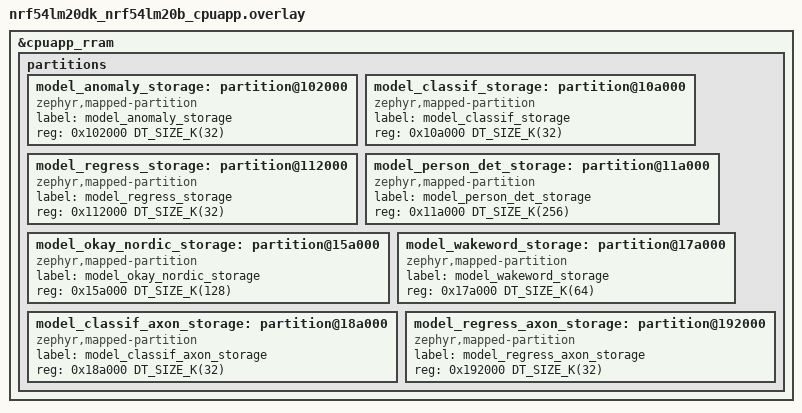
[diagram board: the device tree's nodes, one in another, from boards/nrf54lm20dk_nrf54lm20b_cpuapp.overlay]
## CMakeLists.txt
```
#
# Copyright (c) 2026 Nordic Semiconductor ASA
#
# SPDX-License-Identifier: LicenseRef-Nordic-5-Clause
#

cmake_minimum_required(VERSION 3.20.0)

find_package(Zephyr REQUIRED HINTS $ENV{ZEPHYR_BASE})
project(nrf_edgeai_multi_model_sample)

include(${ZEPHYR_SDK_EDGE_AI_MODULE_DIR}/lib/model_ota/cmake/model_ota.cmake)

set(ANOMALY_MODEL_DIR ${ZEPHYR_SDK_EDGE_AI_MODULE_DIR}/samples/nrf_edgeai/anomaly/src/nrf_edgeai_generated)
set(CLASSIF_MODEL_DIR ${ZEPHYR_SDK_EDGE_AI_MODULE_DIR}/samples/nrf_edgeai/classification/src/nrf_edgeai_generated/Neuton)
set(CLASSIF_AXON_MODEL_DIR ${ZEPHYR_SDK_EDGE_AI_MODULE_DIR}/samples/nrf_edgeai/classification/src/nrf_edgeai_generated/Axon)
set(REGRESS_MODEL_DIR ${ZEPHYR_SDK_EDGE_AI_MODULE_DIR}/samples/nrf_edgeai/regression/src/nrf_edgeai_generated/Neuton)
set(REGRESS_AXON_MODEL_DIR ${ZEPHYR_SDK_EDGE_AI_MODULE_DIR}/samples/nrf_edgeai/regression/src/nrf_edgeai_generated/Axon)
set(CLASSIF_AXON_MODEL_SRC ${CLASSIF_AXON_MODEL_DIR}/nrf_edgeai_user_model.c)
set(CLASSIF_AXON_MODEL_HEADER ${CLASSIF_AXON_MODEL_DIR}/nrf_edgeai_user_model_axon.h)
set(REGRESS_AXON_MODEL_SRC ${REGRESS_AXON_MODEL_DIR}/nrf_edgeai_user_model.c)
set(REGRESS_AXON_MODEL_HEADER ${REGRESS_AXON_MODEL_DIR}/nrf_edgeai_user_model_axon.h)
set(WW_MODEL_DIR ${ZEPHYR_SDK_EDGE_AI_MODULE_DIR}/applications/ww_kws/src/ww/nrf_edgeai_generated)
set(WW_MODEL_SRC ${WW_MODEL_DIR}/nrf_edgeai_user_model.c)
set(WW_MODEL_HEADER ${WW_MODEL_DIR}/nrf_edgeai_user_model_axon.h)
set(PERSON_DET_DIR ${ZEPHYR_SDK_EDGE_AI_MODULE_DIR}/applications/person_detection/src)
set(OKAY_NORDIC_DIR ${ZEPHYR_SDK_EDGE_AI_MODULE_DIR}/samples/axon/axon_low_power/src)

set(NEUTON_MODEL_SOURCES
  ${ANOMALY_MODEL_DIR}/nrf_edgeai_user_model.c
  ${CLASSIF_MODEL_DIR}/nrf_edgeai_user_model.c
  ${REGRESS_MODEL_DIR}/nrf_edgeai_user_model.c
)

set(PERSON_DET_HEADER ${PERSON_DET_DIR}/generated/nrf_axon_model_person_det_.h)
set(OKAY_NORDIC_HEADER ${OKAY_NORDIC_DIR}/generated/nrf_axon_model_okay_nordic.h)

target_include_directories(app PRIVATE include)

target_sources(app PRIVATE
  src/main.c
  src/test_anomaly.c
  src/test_classification.c
  src/test_regression.c
)

if(CONFIG_MULTI_MODEL_AXON)
  target_sources(app PRIVATE
    src/test_classification_axon.c
    src/test_regression_axon.c
    src/test_wakeword.c
    src/test_person_det.c
    src/test_okay_nordic.c
    ${PERSON_DET_DIR}/postprocessing.c
  )
endif()

# Neuton models are partition-loaded when CONFIG_MODEL_OTA_NEUTON is enabled; compiled directly
# into the app otherwise.
if(NOT CONFIG_MODEL_OTA_NEUTON)
  target_sources(app PRIVATE ${NEUTON_MODEL_SOURCES})
endif()

# Edge AI Lab solutions with an Axon backend are partition-loaded when Axon OTA is enabled.
if(CONFIG_MULTI_MODEL_AXON AND NOT CONFIG_MODEL_OTA_AXON)
  target_sources(app PRIVATE
    ${WW_MODEL_SRC}
    ${CLASSIF_AXON_MODEL_SRC}
    ${REGRESS_AXON_MODEL_SRC}
  )
endif()

target_include_directories(app PRIVATE
  ${ANOMALY_MODEL_DIR}
  ${CLASSIF_MODEL_DIR}
  ${REGRESS_MODEL_DIR}
  ${WW_MODEL_DIR}
  ${PERSON_DET_DIR}
  ${PERSON_DET_DIR}/generated
  ${OKAY_NORDIC_DIR}
  ${OKAY_NORDIC_DIR}/generated
)

if(CONFIG_MODEL_OTA_NEUTON)
  model_ota_edgeai_neuton_model(TARGET gear_anomaly SOLUTION_ID 90360 VERSION 1.0.0
                                PARTITION_NODELABEL model_anomaly_storage NEURONS_CAP 20
                                MODEL_SRC ${ANOMALY_MODEL_DIR}/nrf_edgeai_user_model.c)
  model_ota_edgeai_neuton_model(TARGET gesture_class SOLUTION_ID 90449 VERSION 1.0.0
                                PARTITION_NODELABEL model_classif_storage NEURONS_CAP 80
                                MODEL_SRC ${CLASSIF_MODEL_DIR}/nrf_edgeai_user_model.c)
  model_ota_edgeai_neuton_model(TARGET temp_regress SOLUTION_ID 90508 VERSION 1.0.0
                                PARTITION_NODELABEL model_regress_storage NEURONS_CAP 2
                                MODEL_SRC ${REGRESS_MODEL_DIR}/nrf_edgeai_user_model.c)
endif()

if(CONFIG_MULTI_MODEL_AXON AND CONFIG_MODEL_OTA_AXON)
  model_ota_edgeai_axon_model(TARGET wakeword SOLUTION_ID 36711 VERSION 1.0.0
                              PARTITION_NODELABEL model_wakeword_storage
                              MODEL_SRC ${WW_MODEL_SRC} HEADER ${WW_MODEL_HEADER}
                              PERSISTENT_VARS_CAP 1160)
  model_ota_edgeai_axon_model(TARGET classif_axon SOLUTION_ID 36237 VERSION 1.0.0
                              PARTITION_NODELABEL model_classif_axon_storage
                              MODEL_SRC ${CLASSIF_AXON_MODEL_SRC}
                              HEADER ${CLASSIF_AXON_MODEL_HEADER})
  model_ota_edgeai_axon_model(TARGET regress_axon SOLUTION_ID 36025 VERSION 1.0.0
                              PARTITION_NODELABEL model_regress_axon_storage
                              MODEL_SRC ${REGRESS_AXON_MODEL_SRC}
                              HEADER ${REGRESS_AXON_MODEL_HEADER})

  # ALLOCATE_PACKED_OUTPUT: keeps this build path (app-owned storage wired into the
  # linked image's packed_output_buf) covered by every OTA build/flash of this sample.
  model_ota_axon_model(TARGET person_det VERSION 1.0.0
                       PARTITION_NODELABEL model_person_det_storage
                       HEADER ${PERSON_DET_HEADER}
                       ALLOCATE_PACKED_OUTPUT)
  model_ota_axon_model(TARGET okay_nordic VERSION 1.0.0
                       PARTITION_NODELABEL model_okay_nordic_storage
                       HEADER ${OKAY_NORDIC_HEADER}
                       PERSISTENT_VARS_CAP 1160)
endif()

if(CONFIG_MODEL_OTA)
  model_ota_finalize()
endif()
```

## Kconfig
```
#
# Copyright (c) 2026 Nordic Semiconductor ASA
#
# SPDX-License-Identifier: LicenseRef-Nordic-5-Clause
#

menu "Multi-model sample"

config MULTI_MODEL_AXON
	bool "Include the Axon-backed models"
	default y
	help
	  Build and run the models with an Axon backend: the pure Axon ones (person
	  detection, okay_nordic) and the Edge AI Lab solutions whose backend is Axon
	  (wakeword, classification, regression). The Neuton models always build.

config SCORE_THRESHOLD
	int "Person detection score threshold, in per mille"
	default 250
	range 0 1000
	help
	  Confidence score threshold for person detection postprocessing.

config IOU_THRESHOLD
	int "Person detection IoU threshold, in per mille"
	default 450
	range 0 1000
	help
	  Intersection-over-Union threshold for non-maximum suppression.

endmenu

source "Kconfig.zephyr"
```

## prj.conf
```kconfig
#
# Copyright (c) 2026 Nordic Semiconductor ASA
#
# SPDX-License-Identifier: LicenseRef-Nordic-5-Clause
#

CONFIG_NRF_EDGEAI=y
CONFIG_NRF_AXON=y
CONFIG_NRF_AXON_INTERLAYER_BUFFER_SIZE=229376
CONFIG_NRF_AXON_PSUM_BUFFER_SIZE=0
CONFIG_FPU=y
CONFIG_NCS_SAMPLES_DEFAULTS=y
CONFIG_CBPRINTF_FP_SUPPORT=y
CONFIG_SCORE_THRESHOLD=250
CONFIG_IOU_THRESHOLD=450

CONFIG_LOG_MODE_IMMEDIATE=y
CONFIG_ASSERT_NO_MSG_INFO=n
CONFIG_RESET_ON_FATAL_ERROR=n
```

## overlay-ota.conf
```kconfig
#
# Copyright (c) 2026 Nordic Semiconductor ASA
#
# SPDX-License-Identifier: LicenseRef-Nordic-5-Clause
#
# Model-only OTA overlay for the multi_model sample (nRF54LM20 DK boards only): the Neuton
# models, the person-detection/okay_nordic Axon models, and the wakeword/classification/
# regression Edge AI Lab solutions' compiled Axon models are all built as linked partition
# images. Build with:
#   west build -b nrf54lm20dk/nrf54lm20b/cpuapp -- -DEXTRA_CONF_FILE=overlay-ota.conf

CONFIG_MODEL_OTA_TESTING=y
CONFIG_MODEL_OTA=y
CONFIG_MODEL_OTA_NEUTON=y
CONFIG_MODEL_OTA_AXON=y

# model_image_load_*() dependencies.
CONFIG_FLASH=y
CONFIG_CRC=y
```

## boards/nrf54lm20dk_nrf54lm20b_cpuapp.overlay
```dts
/*
 * Copyright (c) 2026 Nordic Semiconductor ASA
 *
 * SPDX-License-Identifier: LicenseRef-Nordic-5-Clause
 */

/*
 * Model-only OTA: repurpose the unused (no-MCUboot) slot1_partition region as dedicated
 * model_storage partitions (three Neuton models + five Axon models, including the Edge AI Lab
 * wakeword/classification/regression solutions' Axon backends).
 * -DEXTRA_CONF_FILE=overlay-ota.conf; harmless (just reserved, unused flash) otherwise.
 *
 * The OTA build emits a standalone <name>_model_partition.hex per model (linked at the matching
 * partition base). Flash one into its partition without disturbing the app or the other models:
 *   nrfutil device program --firmware gear_anomaly_model_partition.hex \
 *       --options chip_erase_mode=ERASE_RANGES_TOUCHED_BY_FIRMWARE,reset=RESET_SYSTEM
 */
/delete-node/ &slot1_partition;

&cpuapp_rram {
	partitions {
		model_anomaly_storage: partition@102000 {
			compatible = "zephyr,mapped-partition";
			label = "model_anomaly_storage";
			reg = <0x102000 DT_SIZE_K(32)>;
		};

		model_classif_storage: partition@10a000 {
			compatible = "zephyr,mapped-partition";
			label = "model_classif_storage";
			reg = <0x10a000 DT_SIZE_K(32)>;
		};

		model_regress_storage: partition@112000 {
			compatible = "zephyr,mapped-partition";
			label = "model_regress_storage";
			reg = <0x112000 DT_SIZE_K(32)>;
		};

		model_person_det_storage: partition@11a000 {
			compatible = "zephyr,mapped-partition";
			label = "model_person_det_storage";
			reg = <0x11a000 DT_SIZE_K(256)>;
		};

		model_okay_nordic_storage: partition@15a000 {
			compatible = "zephyr,mapped-partition";
			label = "model_okay_nordic_storage";
			reg = <0x15a000 DT_SIZE_K(128)>;
		};

		model_wakeword_storage: partition@17a000 {
			compatible = "zephyr,mapped-partition";
			label = "model_wakeword_storage";
			reg = <0x17a000 DT_SIZE_K(64)>;
		};

		model_classif_axon_storage: partition@18a000 {
			compatible = "zephyr,mapped-partition";
			label = "model_classif_axon_storage";
			reg = <0x18a000 DT_SIZE_K(32)>;
		};

		model_regress_axon_storage: partition@192000 {
			compatible = "zephyr,mapped-partition";
			label = "model_regress_axon_storage";
			reg = <0x192000 DT_SIZE_K(32)>;
		};
	};
};
```

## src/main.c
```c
/*
 * Copyright (c) 2026 Nordic Semiconductor ASA
 *
 * SPDX-License-Identifier: LicenseRef-Nordic-5-Clause
 */

#include "test_models.h"

#include <zephyr/kernel.h>
#include <zephyr/logging/log.h>

LOG_MODULE_REGISTER(multi_model, LOG_LEVEL_INF);

int main(void)
{
	LOG_INF("Running local multi-model test (Neuton + Edge AI + Axon models)");

	run_anomaly_tests();
	LOG_INF("Anomaly tests passed");

	run_classification_tests();
	LOG_INF("Classification tests passed");

	run_regression_tests();
	LOG_INF("Regression tests passed");

#ifdef CONFIG_MULTI_MODEL_AXON
	run_classification_axon_tests();
	LOG_INF("Axon classification tests passed");

	run_regression_axon_tests();
	LOG_INF("Axon regression tests passed");

	run_wakeword_tests();
	LOG_INF("Wakeword tests passed");

	run_person_det_tests();
	LOG_INF("Person detection tests passed");

	run_okay_nordic_tests();
	LOG_INF("okay_nordic tests passed");
#endif

	while (1) {
		LOG_INF("All multi-model tests completed");
		k_sleep(K_MSEC(5000));
	}

	return 0;
}
```

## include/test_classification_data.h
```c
/*
 * Copyright (c) 2026 Nordic Semiconductor ASA
 *
 * SPDX-License-Identifier: LicenseRef-Nordic-5-Clause
 */

#ifndef TEST_CLASSIFICATION_DATA_H_
#define TEST_CLASSIFICATION_DATA_H_

#include <nrf_edgeai/nrf_edgeai.h>

static const size_t USER_WINDOW_SIZE = 50;     /* Samples per inference window */
static const size_t USER_UNIQ_INPUTS_NUM = 1;  /* Single input: acceleration magnitude */
static const size_t USER_MODELS_CLASS_NUM = 7; /* 7 parcel state classes */

/**
 *  Class 0: IDLE STATE - Parcel at Rest
 *
 * Characteristics of the idle state:
 *   - Acceleration values cluster tightly around 1000 mG (gravitational acceleration baseline)
 *   - Minimal variation between consecutive samples (stable, static state)
 *   - No significant spikes or sudden changes in acceleration
 *   - Represents a parcel at rest on a surface (shelf, table, ground, stationary truck)
 *
 * Use cases:
 *   - Parcel stored at warehouse awaiting shipment
 *   - Parcel on delivery truck stationary between stops
 *   - Parcel at customer delivery location
 *   - Parcel placed on shelf or table
 *
 * Data characteristics: Consistent baseline with minimal noise, typical for gravitational field
 */
static const flt32_t CLASS_0_PARCEL_IDLE_ACCEL_DATA[] = {
	1019.234877, 1018.652192, 1016.69811,  1019.901583, 1017.029378, 1014.381015, 1016.604559,
	1016.201444, 1016.23062,  1018.555051, 1016.319548, 1017.072842, 1018.494815, 1013.635677,
	1017.41575,  1021.132362, 1018.691935, 1019.848198, 1016.620341, 1011.873442, 1020.299764,
	1018.478126, 1015.541777, 1014.450299, 1013.253033, 1015.282387, 1016.849032, 1021.09152,
	1017.657982, 1013.24848,  1018.48856,  1013.41613,  1018.465645, 1017.460544, 1014.099637,
	1016.850408, 1016.396988, 1016.185508, 1014.927525, 1019.275502, 1017.403871, 1016.319314,
	1018.377489, 1019.466485, 1019.221851, 1013.788435, 1015.948113, 1014.715299, 1018.539064,
	1014.715299,
};

/**
 *  Class 1: SHAKING STATE - Parcel Vibrating or Experiencing Continuous Motion
 *
 * Characteristics of the shaking state:
 *   - Wide variation in acceleration values (ranging 629–3505 mG across the window)
 *   - High-frequency oscillations with rapid changes between consecutive samples
 *   - Peaks and valleys in the signal indicate repetitive shaking or vibration pattern
 *   - Elevated baseline compared to idle state, indicating active motion
 *
 * Use cases:
 *   - Parcel in vehicle traveling on rough or unpaved road
 *   - Parcel being shaken by delivery handler during transport
 *   - Parcel near vibrating machinery or equipment
 *   - Parcel experiencing turbulence during air transport
 *
 * Data characteristics: Oscillatory pattern with significant amplitude variation
 */
static const flt32_t CLASS_1_PARCEL_SHAKING_ACCEL_DATA[] = {
	832.512589,  1272.162323, 1263.232939, 1489.776683, 1859.176281, 1772.024529, 1622.484949,
	1421.231322, 988.9233308, 2904.564726, 1004.390724, 961.4903516, 1569.262094, 1926.891127,
	2159.370306, 1897.586384, 1533.182266, 2626.996728, 1044.248622, 866.9409276, 953.1315255,
	970.2099379, 1587.471444, 1810.551686, 1633.204426, 1730.792617, 2137.291854, 629.6878458,
	1069.066947, 1052.676461, 1091.051232, 1590.295378, 1840.453506, 1829.107198, 1790.32045,
	3505.788281, 1398.574137, 1089.641059, 625.6990249, 854.0307434, 1191.972966, 1523.862829,
	1490.407087, 1600.889671, 1487.519159, 1112.465548, 1909.979213, 1078.403761, 971.6052426,
	872.8287226,
};

/**
 *  Class 2: IMPACT EVENT - Sudden Collision or Drop
 *
 * Characteristics of the impact state:
 *   - Baseline values ~1000–1400 mG (idle/stable state before and after impact)
 *   - Extreme acceleration spike in middle of window (5943–6924 mG, approximately 7x gravity)
 *   - Sharp, isolated peak indicating instantaneous collision or drop event
 *   - Recovery to normal levels immediately after impact spike
 *   - Asymmetric acceleration profile with clear before/after pattern
 *
 * Use cases:
 *   - Parcel dropped from height or accidentally thrown
 *   - Parcel collides with wall, table, or other object during handling
 *   - Parcel experiences sharp impact during loading/unloading operations
 *   - Parcel falls from moving vehicle or conveyor belt
 *
 * Risk Assessment: High risk for potential damage to contents
 * Data characteristics: Baseline + single large impulse, distinctive pattern for detection
 */
static const flt32_t CLASS_2_PARCEL_IMPACT_ACCEL_DATA[] = {
	1015.482154, 1014.753436, 1014.523099, 1012.472024, 1009.822764, 1013.528832, 1010.94256,
	1014.375469, 1010.949774, 1013.925464, 1015.508712, 1012.451178, 968.8407378, 1393.710166,
	5943.221118, 6924.142149, 4296.249304, 3458.151271, 2119.268542, 3263.52814,  1881.500201,
	1479.332158, 1364.573158, 2317.111272, 3159.792859, 2391.741083, 1305.986745, 1169.182085,
	1079.52232,  1048.65378,  1196.683715, 1054.96444,  1147.454278, 971.4221942, 1054.533138,
	1005.604551, 998.3117395, 1026.769424, 991.8001837, 1026.298981, 1007.115343, 1014.293972,
	1007.958389, 1009.272635, 1015.343811, 1013.057529, 1013.781359, 1012.335122, 1011.281924,
	1014.560157,

};

/**
 *  Class 3: FREE FALL STATE - Parcel Unsupported in Air
 *
 * Characteristics of the free fall state:
 *   - Very low acceleration values (15–82 mG, approximately 0.1–0.8x gravity)
 *   - Consistent low baseline throughout the window
 *   - Absence of gravitational acceleration component (sensor in inertial frame)
 *   - Minimal variation, indicating uniform free-fall motion
 *   - Dramatic difference from idle state (which is ~1000 mG)
 *
 * Use cases:
 *   - Parcel dropped and falling under gravity alone
 *   - Parcel suspended or lifted without support (losing contact with surface)
 *   - Parcel in flight during drone or aerial delivery
 *   - Parcel ejected from moving vehicle
 *
 * Risk Assessment: Critical - indicates loss of support or drop in progress
 * Data characteristics: Low constant acceleration, inverse of idle state pattern
 */
static const flt32_t CLASS_3_PARCEL_FREE_FALL_ACCEL_DATA[] = {
	36.87388192, 32.60300207, 29.4674831,  32.69417905, 34.11116509, 33.15887284, 33.85626394,
	32.15342346, 52.59657571, 36.6853006,  38.54968347, 35.5160419,	 48.3840372,  47.2611057,
	39.59571977, 39.79519569, 47.38188498, 50.11275303, 55.69724245, 64.75752645, 70.27411802,
	68.7569314,  68.42144611, 66.124,      75.38968258, 58.17801248, 81.70503133, 81.17282629,
	74.35437106, 62.17788379, 63.89306679, 46.27838078, 43.04231927, 39.9609133,  39.70982871,
	34.28699252, 43.81753603, 27.73132727, 27.37479921, 46.95272669, 24.82332774, 30.18310574,
	37.00201876, 44.0080229,  39.55886449, 162.4691915, 50.70270683, 15.83370127, 75.95418619,
	82.38026851,

};

/**
 *  Class 4: CARRYING STATE - Being Transported by Handler
 *
 * Characteristics of the carrying state:
 *   - Moderate acceleration variation (793–1350 mG range)
 *   - Gradual, smooth transitions between acceleration values
 *   - No sharp spikes or sudden changes characteristic of impacts
 *   - Pattern reflects natural human motion (walking, arm swinging, body sway)
 *   - Organized rhythmic fluctuation corresponding to periodic step patterns
 *   - Distinctly different from mechanical vibration (more organic signal)
 *
 * Use cases:
 *   - Delivery courier walking with parcel in hand or in arms
 *   - Handler carrying parcel to customer door
 *   - Parcel held during package transfer operations
 *   - Manual transport up stairs or through buildings
 *
 * Quality Assessment: Normal, gentle handling with no impact events
 * Data characteristics: Smooth oscillatory pattern reflecting human locomotion
 */
static const flt32_t CLASS_4_PARCEL_CARRYING_ACCEL_DATA[] = {
	1076.406463, 1109.062753, 1161.315764, 1237.303839, 1304.16174,	 1350.922984, 1241.533046,
	1058.547397, 936.9035098, 903.8836329, 909.9999218, 969.2561481, 1018.445741, 978.245237,
	898.4931508, 820.9886822, 793.33496,   823.5297855, 861.7252695, 896.6489743, 934.029546,
	949.6519496, 934.6501455, 959.1392024, 1009.025175, 1096.235981, 1187.678992, 1166.728833,
	1151.409319, 1130.995037, 1206.818376, 1211.209389, 1234.399883, 1316.256909, 1192.097129,
	935.7616639, 849.2381705, 855.3595664, 875.9844676, 940.2683021, 979.1213199, 974.3049546,
	894.6000374, 830.5673266, 806.1867451, 848.9594567, 879.9365677, 904.6198895, 916.9955333,
	963.7698856,

};

/**
 *  Class 5: IN CAR STATE - Parcel Inside Vehicle During Transport
 *
 * Characteristics of the in-car state:
 *   - Moderate, steady acceleration (920–1200 mG throughout the window)
 *   - Smoother variation compared to hand-carried courier handling
 *   - Vehicle suspension system and road vibration create gentle oscillations
 *   - Less organic (human-like) motion pattern; more mechanical (vehicle-like) signature
 *   - Baseline elevated from idle (~1000 mG) due to vehicle motion
 *
 * Use cases:
 *   - Parcel on shelf or floor of moving delivery van
 *   - Parcel in cargo area of delivery truck during road transport
 *   - Parcel on seat or seat belt secured in personal vehicle
 *   - Parcel in container being transported between warehouses
 *
 * Quality Assessment: Protected transport with minimal manual handling and impacts
 * Data characteristics: Smooth mechanical oscillation from vehicle suspension
 */
static const flt32_t CLASS_5_PARCEL_IN_CAR_ACCEL_DATA[] = {
	1020.14299,  1172.412078, 974.2434799, 1081.052374, 936.2345817, 1076.324048, 952.8650187,
	958.4387398, 919.7921364, 945.1008577, 1010.444803, 1048.425866, 954.5281871, 934.6416098,
	1039.243636, 983.2000815, 1106.467282, 1022.459808, 905.5254547, 1021.745856, 1036.285954,
	1061.250757, 1039.194138, 940.8242922, 1076.395069, 1059.220609, 1131.268418, 973.8779736,
	1029.466912, 1062.131636, 1077.031533, 1055.016753, 972.2285251, 1046.442069, 993.0253833,
	1035.990238, 1008.750742, 1035.737579, 1041.367931, 1042.022619, 960.7748412, 1037.639083,
	977.0186869, 990.7190264, 1054.852976, 979.9177917, 997.7978969, 1034.345125, 959.2851854,
	1041.668807,
};

/**
 *  Class 6: PLACED STATE - Active Placement or Lowering Motion
 *
 * Characteristics of the placed state:
 *   - Starts with variable mid-range acceleration (1000–1400 mG)
 *   - Sharp drop to very low value (~76 mG) in middle of window (near free-fall)
 *   - Recovery back to stable ~1000 mG (landed and resting on surface)
 *   - Signature pattern: acceleration during descent followed by impact landing
 *   - Asymmetric temporal profile: active descent phase then static rest phase
 *   - Distinctive from pure free fall (has initial and final support)
 *
 * Use cases:
 *   - Parcel being gently placed down on shelf or table
 *   - Parcel being lowered to ground by handler or crane
 *   - Parcel being set down in customer delivery location
 *   - Parcel being suspended then released on support surface
 *
 * Quality Assessment: Intentional placement, potentially fragile/careful handling
 * Data characteristics: Descent profile with clear phase transition from motion to rest
 */
static const flt32_t CLASS_6_PARCEL_PLACED_ACCEL_DATA[] = {
	1028.084177, 1009.771942, 1023.977186, 1012.436213, 1020.685482, 1018.459741, 1013.2669,
	1402.760074, 1072.973569, 1044.170967, 996.3176143, 1090.362426, 1024.921702, 1037.91844,
	1052.900034, 1062.920713, 1020.651183, 966.0045051, 906.5110973, 871.8735271, 824.1462199,
	799.1876862, 776.2963823, 765.3527818, 802.7631891, 1163.179632, 1016.619697, 76.78637744,
	1418.807213, 1005.875935, 1033.329744, 1119.948199, 946.126825,	 1083.038163, 949.8881454,
	1064.367743, 978.8891064, 1023.622866, 1026.007989, 1002.963002, 1026.46044,  1008.698302,
	1032.013223, 1016.890865, 1016.071373, 1022.803209, 1009.949278, 1007.64987,  997.3304425,
	1062.455154,
};

/* Enumeration of parcel state classes */
typedef enum {
	MODEL_CLASS_IDLE = 0,
	MODEL_CLASS_SHAKING,
	MODEL_CLASS_IMPACT,
	MODEL_CLASS_FREE_FALL,
	MODEL_CLASS_CARRYING,
	MODEL_CLASS_IN_CAR,
	MODEL_CLASS_PLACED,
} user_model_class_t;

/* Human-readable labels for each parcel state class */
static const char *const USER_MODEL_LABELS_STR[] = {
	[MODEL_CLASS_IDLE] = "Idle",	     [MODEL_CLASS_SHAKING] = "Shaking",
	[MODEL_CLASS_IMPACT] = "Impact",     [MODEL_CLASS_FREE_FALL] = "Free Fall",
	[MODEL_CLASS_CARRYING] = "Carrying", [MODEL_CLASS_IN_CAR] = "in Car",
	[MODEL_CLASS_PLACED] = "Placed",
};


#endif /* TEST_CLASSIFICATION_DATA_H_ */
```

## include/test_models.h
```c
/*
 * Copyright (c) 2026 Nordic Semiconductor ASA
 *
 * SPDX-License-Identifier: LicenseRef-Nordic-5-Clause
 */

#ifndef TEST_MODELS_H_
#define TEST_MODELS_H_

void run_anomaly_tests(void);
void run_classification_tests(void);
void run_regression_tests(void);

#ifdef CONFIG_MULTI_MODEL_AXON
void run_classification_axon_tests(void);
void run_regression_axon_tests(void);
void run_wakeword_tests(void);
void run_person_det_tests(void);
void run_okay_nordic_tests(void);
#endif

#endif /* TEST_MODELS_H_ */
```

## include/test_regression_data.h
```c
/*
 * Copyright (c) 2026 Nordic Semiconductor ASA
 *
 * SPDX-License-Identifier: LicenseRef-Nordic-5-Clause
 */

#ifndef TEST_REGRESSION_DATA_H_
#define TEST_REGRESSION_DATA_H_

#include <nrf_edgeai/nrf_edgeai.h>

static const size_t USER_WINDOW_SIZE = 1;	 /* Samples per inference window */
static const size_t USER_UNIQ_INPUTS_NUM = 9;	 /* Gas sensor and environmental input features */
static const size_t USER_MODELS_OUTPUTS_NUM = 1; /* Single air quality prediction output */
static const flt32_t INVALID_PREDICTION_VALUE = -9999.0f; /* Invalid prediction indicator */
static const flt32_t EXPECTED_MODEL_MAE = 2.0f; /* Expected Mean Absolute Error for validation */

/**
 * @brief Test Dataset Structure and Values
 *
 * This structure defines the schema for test samples:
 * - COGT: CO sensor (main carbon monoxide detector)
 * - PT08S1-5: Five metal oxide semiconductor (MOS) sensors:
 *   * PT08S1: CO sensor output
 *   * PT08S2: NMHC (non-methane hydrocarbons) sensor
 *   * PT08S3: NOx (nitrogen oxides) sensor
 *   * PT08S4: NO2 (nitrogen dioxide) sensor
 *   * PT08S5: O3 (ozone) sensor
 * - T: Temperature in Celsius (affects pollutant concentration and sensor response)
 * - RH: Relative Humidity in percentage (influences sensor readings and pollutant behavior)
 * - AH: Absolute Humidity in kg/m³ (moisture content in air)
 * - target: Ground truth air quality value (used for validation)
 *
 * @note All sensor values are normalized or raw readings from the measurement device.
 * The 29 test samples cover various environmental conditions to validate model performance
 * across different temperature, humidity, and pollution levels.
 */
struct {
	flt32_t COGT;	/**< CO sensor reading */
	flt32_t PT08S1; /**< PT08 MOS sensor 1 (CO) */
	flt32_t PT08S2; /**< PT08 MOS sensor 2 (NMHC) */
	flt32_t PT08S3; /**< PT08 MOS sensor 3 (NOx) */
	flt32_t PT08S4; /**< PT08 MOS sensor 4 (NO2) */
	flt32_t PT08S5; /**< PT08 MOS sensor 5 (O3) */
	flt32_t T;	/**< Temperature in Celsius */
	flt32_t RH;	/**< Relative Humidity in percentage */
	flt32_t AH;	/**< Absolute Humidity in kg/m³ */
	flt32_t target; /**< Ground truth air quality value */
} static const USER_INPUT_DATA[] = {
	[0] = {2.7, 1146, 1125, 846, 1511, 1016, 33.4, 20.3, 1.027, 14.3},
	[1] = {3.3, 1272, 1328, 567, 2085, 1463, 19.6, 54.3, 1.2278, 21.1},
	[2] = {0.6, 919, 571, 1017, 1082, 521, 13.5, 63.8, 0.9801, 1.8},
	[3] = {1.7, 1162, 1019, 622, 1904, 1178, 27.9, 56.5, 2.0895, 11.1},
	[4] = {2.7, 1381, 1227, 595, 1903, 1845, 29.8, 33.1, 1.3693, 17.6},
	[5] = {1.1, 1010, 679, 854, 1046, 889, 5, 82.9, 0.73, 3.4},
	[6] = {1.9, 1055, 1037, 635, 1632, 1161, 25.3, 41.7, 1.3247, 11.6},
	[7] = {3.4, 1417, 1303, 635, 1964, 1752, 20.7, 40, 0.9639, 20.2},
	[8] = {2, 1273, 988, 563, 1387, 1257, 24.1, 33.3, 0.9881, 10.3},
	[9] = {4.8, 1435, 1429, 499, 2072, 1449, 21.7, 59.1, 1.5115, 25},
	[10] = {1, 1003, 635, 829, 1235, 711, 13.7, 80.6, 1.2528, 2.7},
	[11] = {1.3, 1259, 1152, 610, 1165, 1569, 8.2, 36.8, 0.4016, 15.1},
	[12] = {2.7, 1229, 1114, 598, 1723, 1247, 19.7, 0.73, 0.6708, 13.9},
	[13] = {2.8, 1261, 1258, 629, 1813, 1315, 43.4, 14.8, 1.2882, 18.6},
	[14] = {1.3, 997, 752, 837, 952, 724, 11.8, 34.4, 0.4758, 4.8},
	[15] = {1.3, 942, 846, 980, 1615, 905, 21.7, 50.8, 1.3019, 6.7},
	[16] = {0.6, 883, 518, 1135, 962, 606, 3.3, 84.5, 0.6612, 1.2},
	[17] = {3.2, 1174, 1264, 670, 1598, 1287, 28.9, 21.3, 0.8382, 18.8},
	[18] = {0.5, 748, 595, 1208, 1089, 677, 12.8, 0.598, 0.8801, 2.2},
	[19] = {1.4, 920, 783, 1046, 1550, 588, 24.5, 0.384, 1.1669, 5.4},
	[20] = {1.3, 906, 790, 893, 837, 642, 12.3, 19.3, 0.274, 5.5},
	[21] = {0.6, 882, 563, 978, 936, 660, 8.9, 0.527, 0.6034, 1.7},
	[22] = {3.4, 1403, 1443, 508, 2234, 1811, 25.2, 0.386, 1.2215, 25.6},
	[23] = {3.9, 1297, 1102, 507, 1375, 1583, 18.2, 0.363, 0.7487, 13.6},
	[24] = {1.3, 987, 800, 989, 1462, 658, 15.5, 0.571, 0.996, 5.7},
	[25] = {1.3, 869, 866, 1107, 1212, 596, 0.238, 0.145, 0.4222, 7.2},
	[26] = {3.2, 1336, 1340, 540, 2049, 1400, 21.3, 0.635, 1.5941, 21.6},
	[27] = {1, 955, 723, 1129, 1393, 559, 27.7, 0.258, 0.9467, 4.2},
	[28] = {4.3, 1373, 1364, 597, 2005, 1745, 33.7, 0.226, 1.1658, 22.5}};


#endif /* TEST_REGRESSION_DATA_H_ */
```

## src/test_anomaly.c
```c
/*
 * Copyright (c) 2025 Nordic Semiconductor ASA
 *
 * SPDX-License-Identifier: LicenseRef-Nordic-5-Clause
 */

/**
 * @file test_anomaly.c
 * @brief Mechanical Gear Anomaly Detection Model using Vibration Analysis
 *
 * This file implements an anomaly detection neural network model for monitoring gear health
 * using multi-axis vibration data, enabling predictive maintenance and early fault detection.
 *
 * @details
 * **Model Purpose:** Detect abnormal vibration patterns indicating gear degradation, wear,
 * misalignment, or bearing failure using machine learning on dual-axis accelerometer data.
 *
 * **Input Features (2 total):**
 *   - Sensor 1: X-axis vibration (radial direction) in m/s^2
 *   - Sensor 2: Y-axis vibration (axial/tangential direction) in m/s^2
 *   - Data format: Interleaved pairs [X1, Y1, X2, Y2, ...] for streaming input
 *   - Window size: 128 consecutive samples per inference cycle
 *
 * **Output:**
 *   - Anomaly Score: Single floating-point value (0.0 to 1.0+)
 *     - Score < 0.000025: Normal operation (healthy gear, no maintenance needed)
 *     - Score >= 0.000025: Anomaly detected (schedule maintenance alert)
 *
 * **Vibration Characteristics:**
 *   - Healthy Gear: Regular, predictable signature (2.42-2.52 m/s^2, tight distribution)
 *     * Dominated by mesh frequency and harmonics
 *     * Stable periodic oscillation, minimal variation
 *     * No impulsive events or amplitude modulation
 *   - Faulty Gear: Erratic, irregular signature (2.40-2.56 m/s^2, wider spread)
 *     * Sidebands and modulation indicating tooth wear/crack
 *     * Random impulsive events from surface degradation
 *     * Non-stationary pattern indicating bearing failure or misalignment
 *
 * **Applications:**
 *   - Predictive maintenance for rotating machinery (pumps, motors, compressors)
 *   - Early fault detection before catastrophic failure occurs
 *   - Condition-based maintenance scheduling to reduce downtime and costs
 *   - Asset health monitoring across industrial facilities
 *   - Quality control and validation of newly manufactured gear units
 *
 * **Validation Approach:**
 *   The model is validated on two representative vibration datasets: one from a healthy
 *   gear (normal operation) and one from a faulty gear (degraded condition). The model
 *   must correctly distinguish between states to confirm proper anomaly detection.
 */

#include <nrf_edgeai/nrf_edgeai.h>

#include <zephyr/kernel.h>
#include <zephyr/logging/log.h>
#include <stdio.h>

LOG_MODULE_REGISTER(multi_anomaly, LOG_LEVEL_INF);

nrf_edgeai_t *nrf_edgeai_user_model_90360(void);

#if defined(CONFIG_MODEL_OTA_NEUTON)
#include <model_ota/model_ota_edgeai.h>

MODEL_OTA_EDGEAI_LOAD_DECL(90360);
#endif

/**
 * @brief Model Configuration Constants
 *
 * These constants define the shape and structure of the gear anomaly detector:
 * - USER_WINDOW_SIZE: Number of vibration samples accumulated before running inference.
 *   A window of 128 samples captures sufficient temporal detail in gear vibration patterns.
 * - USER_UNIQ_INPUTS_NUM: Total number of input features to the model.
 *   Set to 2 for the dual-axis accelerometer (X and Y vibration components).
 * - USER_ANOMALY_THRESHOLD: Classification threshold for anomaly detection.
 *   Scores above this threshold indicate abnormal gear operation requiring maintenance.
 */
#define USER_WINDOW_SIZE       128	 /* Samples per inference window */
#define USER_UNIQ_INPUTS_NUM   2	 /* 2 vibration sensors: axis X and Y */
#define USER_ANOMALY_THRESHOLD 0.000025f /* Anomaly score threshold, high sensitivity */
#define INVALID_ANOMALY_SCORE  10000.0f	 /* Invalid score for test validation */

/**
 *  Healthy Gear Vibration Baseline Data
 *
 * This dataset contains vibration measurements from a well-maintained mechanical gear
 * operating under normal conditions. Used to validate that the model correctly identifies
 * healthy gear operation with a low anomaly score.
 *
 * Data characteristics:
 *   - Sensor 1 (X-axis): Tightly clustered values around 2.42-2.52 m/s^2
 *   - Sensor 2 (Y-axis): Tightly clustered values around 2.42-2.52 m/s^2
 *   - Tight, consistent distribution across both axes
 *   - Regular, predictable oscillation pattern
 *   - Signal periodicity dominated by gear mesh frequency and harmonics
 *   - Stable baseline with no sudden spikes or amplitude modulation
 *
 * Data format:
 *   Interleaved pairs: [X1, Y1, X2, Y2, X3, Y3, ...]
 *   Total 256 values: 128 samples × 2 axes
 *
 * Expected model output:
 *   Anomaly score << USER_ANOMALY_THRESHOLD (well below threshold, indicating healthy state)
 *   Model confidence: High certainty of normal operation
 */
static const flt32_t GOOD_GEAR_MECH_VIBRATION_DATA_2AXIS[USER_WINDOW_SIZE *
							 USER_UNIQ_INPUTS_NUM] = {
	2.523464899, 2.43016754,  2.521493825, 2.430003284, 2.522479362, 2.429674773, 2.521329569,
	2.431810097, 2.522479362, 2.43131733,  2.519358495, 2.430496051, 2.521986593, 2.430660307,
	2.521001056, 2.431153074, 2.521001056, 2.431153074, 2.523957667, 2.431974352, 2.522150849,
	2.430003284, 2.521822337, 2.429839029, 2.524943204, 2.428853495, 2.522643618, 2.429839029,
	2.522479362, 2.430660307, 2.521658081, 2.429839029, 2.520015519, 2.430824563, 2.521001056,
	2.432138608, 2.521822337, 2.431810097, 2.520672544, 2.431645841, 2.521493825, 2.430988818,
	2.522315105, 2.43131733,  2.521986593, 2.431645841, 2.522315105, 2.430496051, 2.522643618,
	2.429510518, 2.522315105, 2.43016754,  2.521165312, 2.429674773, 2.522150849, 2.429510518,
	2.521822337, 2.429839029, 2.521329569, 2.43016754,  2.521493825, 2.429839029, 2.522479362,
	2.429346262, 2.521986593, 2.430660307, 2.521493825, 2.430988818, 2.520344032, 2.430331796,
	2.521165312, 2.429182006, 2.5208368,   2.431974352, 2.522479362, 2.431974352, 2.521329569,
	2.432631375, 2.521165312, 2.431153074, 2.522643618, 2.431810097, 2.523629155, 2.431153074,
	2.52297213,  2.430824563, 2.522479362, 2.430331796, 2.521493825, 2.430331796, 2.520344032,
	2.429510518, 2.522807874, 2.43131733,  2.523629155, 2.429839029, 2.521658081, 2.430824563,
	2.521658081, 2.430824563, 2.521001056, 2.429839029, 2.522479362, 2.430003284, 2.524121923,
	2.428360728, 2.523136386, 2.429510518, 2.521329569, 2.430331796, 2.520672544, 2.431974352,
	2.523629155, 2.431153074, 2.521822337, 2.431153074, 2.521165312, 2.431810097, 2.520508288,
	2.432631375, 2.5208368,	  2.432138608, 2.521329569, 2.431153074, 2.523136386, 2.431153074,
	2.523793411, 2.431645841, 2.520179775, 2.431153074, 2.520672544, 2.431810097, 2.524450436,
	2.429346262, 2.522150849, 2.428689239, 2.521493825, 2.429674773, 2.521493825, 2.429674773,
	2.522150849, 2.430660307, 2.522643618, 2.430496051, 2.522479362, 2.431153074, 2.521165312,
	2.431153074, 2.522807874, 2.429839029, 2.523300642, 2.430824563, 2.52297213,  2.429346262,
	2.522150849, 2.429017751, 2.522150849, 2.430988818, 2.523629155, 2.430496051, 2.523136386,
	2.430660307, 2.522150849, 2.430331796, 2.522479362, 2.430988818, 2.522643618, 2.431974352,
	2.522479362, 2.431153074, 2.522807874, 2.431974352, 2.521329569, 2.432631375, 2.520344032,
	2.431481585, 2.521822337, 2.430003284, 2.522643618, 2.43131733,	 2.523793411, 2.430496051,
	2.522315105, 2.430824563, 2.522807874, 2.430824563, 2.523629155, 2.429510518, 2.523464899,
	2.429182006, 2.521822337, 2.430496051, 2.521822337, 2.430824563, 2.521329569, 2.432302864,
	2.522315105, 2.432467119, 2.521822337, 2.432302864, 2.522315105, 2.432138608, 2.522150849,
	2.430824563, 2.524778948, 2.430003284, 2.522643618, 2.430003284, 2.522479362, 2.430988818,
	2.522807874, 2.432795631, 2.522479362, 2.430496051, 2.523300642, 2.430003284, 2.521658081,
	2.430003284, 2.5208368,	  2.43131733,  2.523629155, 2.431481585, 2.523300642, 2.430660307,
	2.522315105, 2.430660307, 2.522807874, 2.430824563, 2.522315105, 2.430660307, 2.521493825,
	2.430003284, 2.523793411, 2.43016754,  2.523300642, 2.430496051, 2.521493825, 2.430331796,
	2.521822337, 2.43016754,  2.521822337, 2.428853495, 2.523300642, 2.430331796, 2.522150849,
	2.43016754,  2.522315105, 2.431153074, 2.521658081, 2.432302864, 2.523136386, 2.430496051,
	2.521165312, 2.431481585, 2.5208368,   2.430988818,
};

/**
 * Anomalous Gear Vibration Data - Faulty Operation
 *
 * This dataset contains vibration measurements from a defective mechanical gear exhibiting
 * abnormal operating conditions. Used to validate that the model correctly identifies gear
 * faults with an anomaly score above the detection threshold.
 *
 * Data characteristics of defective gear:
 *   - Sensor 1 (X-axis): Wider range 2.40-2.56 m/s^2 (vs. healthy 2.42-2.52 m/s^2)
 *   - Sensor 2 (Y-axis): Wider range 2.40-2.56 m/s^2 (greater variation than healthy)
 *   - Erratic, unpredictable fluctuations across both axes
 *   - Irregular variation pattern with sudden amplitude changes
 *   - Modulation sidebands indicating gear tooth damage or misalignment
 *   - Random impulsive events with high-amplitude spikes (reaching 2.56+ m/s^2)
 *   - Non-stationary characteristics indicating evolving fault condition
 *
 * Root causes of this vibration signature:
 *   - Gear tooth crack or progressive wear
 *   - Bearing failure or severe misalignment
 *   - Gear mesh surface degradation and pitting
 *   - Lubrication failure or contamination
 *
 * Data format:
 *   Interleaved pairs: [X1, Y1, X2, Y2, X3, Y3, ...]
 *   Total 256 values: 128 samples × 2 axes
 *
 * Expected model output:
 *   Anomaly score >= USER_ANOMALY_THRESHOLD (at or above threshold, indicating fault)
 *   Model confidence: High certainty of abnormal operation
 *   Risk Level: High - maintenance or replacement required
 */
static const flt32_t ANOMALOUS_GEAR_MECH_VIBRATION_DATA_2AXIS[USER_WINDOW_SIZE *
							      USER_UNIQ_INPUTS_NUM] = {
	2.514595067, 2.435423722, 2.508846103, 2.433288398, 2.516730396, 2.438216068, 2.542682877,
	2.42638966,  2.520179775, 2.425732638, 2.532006221, 2.424582848, 2.51870147,  2.437723301,
	2.546625028, 2.418998157, 2.497019667, 2.43739479,  2.521493825, 2.428032217, 2.501290324,
	2.431810097, 2.532663246, 2.419326669, 2.523300642, 2.448892691, 2.498169459, 2.435423722,
	2.519687007, 2.437559046, 2.5208368,   2.44544332,  2.526257254, 2.442158206, 2.497676691,
	2.402736858, 2.538412214, 2.434602443, 2.514923579, 2.436573511, 2.530692171, 2.409471334,
	2.51360953,  2.421954758, 2.495377107, 2.423104548, 2.511309945, 2.470245947, 2.546460772,
	2.426553916, 2.495705619, 2.441008415, 2.52510746,  2.427703705, 2.512788249, 2.432795631,
	2.551716974, 2.439858625, 2.526750022, 2.406843246, 2.519851263, 2.441172671, 2.522479362,
	2.422776036, 2.491927731, 2.463511457, 2.549088872, 2.389924931, 2.490613683, 2.460390596,
	2.543668415, 2.404050902, 2.501947348, 2.442486717, 2.52987089,	 2.415877301, 2.508189079,
	2.44544332,  2.505889494, 2.433452653, 2.558451484, 2.422611781, 2.532498989, 2.433781165,
	2.543668415, 2.429346262, 2.531020683, 2.422119014, 2.513281018, 2.425896893, 2.540054777,
	2.427375194, 2.519687007, 2.456284201, 2.505889494, 2.429182006, 2.524614692, 2.418998157,
	2.520344032, 2.449221202, 2.541697339, 2.442815228, 2.528392584, 2.427210938, 2.5208368,
	2.420147947, 2.540876058, 2.450370993, 2.527407047, 2.405364946, 2.504082677, 2.415384535,
	2.514102298, 2.433781165, 2.509667384, 2.457926759, 2.53463432,	 2.426718172, 2.511638457,
	2.411606656, 2.515087835, 2.452834829, 2.537755189, 2.442322461, 2.545146721, 2.411935168,
	2.533648783, 2.42491136,  2.514923579, 2.418505391, 2.52987089,	 2.410128357, 2.521165312,
	2.423268803, 2.528228328, 2.44971397,  2.503589909, 2.431810097, 2.520015519, 2.425404126,
	2.500140532, 2.450042481, 2.527735559, 2.445936087, 2.49981202,	 2.44199395,  2.519358495,
	2.419819435, 2.53857647,  2.444457786, 2.560258304, 2.423104548, 2.504575445, 2.434109676,
	2.54563949,  2.431153074, 2.506382262, 2.436902023, 2.528064072, 2.428360728, 2.519194239,
	2.446428855, 2.498662227, 2.429839029, 2.530856427, 2.439037347, 2.512952506, 2.44544332,
	2.502604372, 2.45710548,  2.530527915, 2.424582848, 2.528064072, 2.415713046, 2.537590933,
	2.451520783, 2.541368827, 2.414891768, 2.500797556, 2.436573511, 2.52855684,  2.417519857,
	2.509667384, 2.435587977, 2.507039286, 2.424582848, 2.526585766, 2.426718172, 2.501618836,
	2.436245,    2.532827502, 2.433781165, 2.537590933, 2.428032217, 2.519194239, 2.436409256,
	2.52642151,  2.428360728, 2.554016562, 2.42228327,  2.509174615, 2.451028016, 2.522315105,
	2.434438188, 2.511145688, 2.432467119, 2.480594069, 2.423925826, 2.546296515, 2.427867961,
	2.506710774, 2.451356527, 2.513938042, 2.421954758, 2.552045486, 2.448892691, 2.507367798,
	2.419983691, 2.56633579,  2.428196472, 2.521658081, 2.433124142, 2.522643618, 2.436245,
	2.540547545, 2.436245,	  2.505232469, 2.428853495, 2.512623993, 2.431645841, 2.521001056,
	2.410456868, 2.513116762, 2.42638966,  2.538412214, 2.442322461, 2.529542378, 2.449549714,
	2.520344032, 2.425404126, 2.566007278, 2.426882427, 2.527899816, 2.432467119, 2.526585766,
	2.436409256, 2.52987089,  2.432467119, 2.480429813, 2.421954758, 2.537426676, 2.421297736,
	2.503918421, 2.430660307, 2.487328563, 2.430988818,
};

/** @brief Runs the trained neural network model on dual-axis vibration data.
 *
 * Parameters:
 *   @param[in] p_user_model: Pointer to pre-trained anomaly detection model
 *   @param[in] p_input_data: Array of interleaved [X, Y] acceleration pairs
 *   @param[in] data_len: Total number of data values (128 samples x 2 axes = 256)
 *
 * Process:
 *   1. Extract sensor pair (X, Y) for each sample
 *   2. Feed one pair at a time to simulate streaming sensor input
 *   3. Model accumulates 128 samples into its input window
 *   4. When window fills, inference automatically triggers
 *   5. Compute anomaly score based on learned feature representation
 *   6. Return single score indicating anomaly likelihood
 *
 * Return:
 *   Anomaly score (float): 0.0 = definitely healthy
 *   Interpretation:
 *     score < USER_ANOMALY_THRESHOLD -> Healthy gear (pass maintenance check)
 *     score >= USER_ANOMALY_THRESHOLD > Anomalous gear (schedule maintenance alert)
 */
static flt32_t model_predict(nrf_edgeai_t *p_user_model, const flt32_t *p_input_data,
			     size_t data_len)
{
	nrf_edgeai_err_t res;

	/* Initialize with high value (indicates failure) */
	flt32_t anomaly_score = INVALID_ANOMALY_SCORE;

	/* Feed vibration samples to Edge AI runtime in streaming mode */
	for (size_t i = 0; i < data_len; i += USER_UNIQ_INPUTS_NUM) {
		/* Extract one sample pair: [X_acceleration, Y_acceleration] */
		flt32_t input_sample[USER_UNIQ_INPUTS_NUM];

		input_sample[0] = p_input_data[i];     /* Sensor 1: X-axis */
		input_sample[1] = p_input_data[i + 1]; /* Sensor 2: Y-axis */

		/* Feed this sample pair into the model's windowing buffer */
		res = nrf_edgeai_feed_inputs(p_user_model, input_sample, 1 * USER_UNIQ_INPUTS_NUM);

		if (res == NRF_EDGEAI_ERR_SUCCESS) {
			/* Input buffer has reached 128 samples - run inference on the complete
			 * window
			 */
			res = nrf_edgeai_run_inference(p_user_model);

			/* Check that inference executed successfully */
			if (res == NRF_EDGEAI_ERR_SUCCESS) {
				/* Extract anomaly score from model's decoded output */
				anomaly_score = p_user_model->decoded_output.anomaly.score;
				break;
			}
		}
	}

	return anomaly_score;
}

/**
 * @brief Gear Anomaly Detection Model Validation Entry Point
 *
 * This function orchestrates the complete validation workflow for the gear anomaly
 * detection model. It initializes the neural network, runs inference on healthy and
 * faulty gear vibration data, and validates anomaly detection accuracy.
 *
 * **Workflow:**
 * 1. Retrieve the pre-trained gear anomaly detection model
 * 2. Validate model configuration matches expected parameters:
 *    - Input window size: 128 vibration samples
 *    - Input features: 2 (X and Y axis accelerometers)
 *    - Output values: 1 (anomaly score)
 * 3. Initialize the Edge AI runtime for neural network execution
 * 4. For each of the 2 test cases:
 *    a. Feed vibration data one sample pair at a time
 *    b. Model accumulates 128 samples into window
 *    c. Run model inference to compute anomaly score
 *    d. Compare score against threshold (USER_ANOMALY_THRESHOLD)
 *    e. Verify detection matches expected gear condition
 *
 * **Validation Metrics:**
 * The anomaly score indicates gear health status:
 * - Score < USER_ANOMALY_THRESHOLD: Normal operation (healthy gear, no maintenance needed)
 * - Score >= USER_ANOMALY_THRESHOLD: Anomaly detected (faulty gear, maintenance required)
 * - Correct classification validates model anomaly detection performance
 * - Model confidence determined by score magnitude relative to threshold
 *
 * **Test Coverage:**
 * The 2 test cases validate critical gear operating scenarios:
 * - Healthy gear: Regular, predictable vibration (2.42-2.52 m/s^2 tight distribution)
 * - Faulty gear: Erratic, irregular vibration (2.40-2.56 m/s^2, wider distribution)
 * - Covers the complete spectrum from normal to degraded gear condition
 * - Validates model suitability for predictive maintenance applications
 *
 * **Practical Application:**
 * Once validated, this model enables continuous monitoring of rotating machinery,
 * detecting early signs of gear wear, cracks, misalignment, or bearing failure,
 * triggering maintenance alerts before catastrophic failures occur.
 *
 */
void run_anomaly_tests(void)
{
	/*  Get user generated model pointer */
#if defined(CONFIG_MODEL_OTA_NEUTON)
	/* Model-only OTA: load the payload from its flash partition (XIP) at runtime. */
	nrf_edgeai_t *p_user_model;

	if (nrf_edgeai_load_user_model_90360(&p_user_model) != MODEL_IMAGE_OK) {
		LOG_WRN("No valid anomaly model image in model_anomaly_storage - skipping (flash "
			"gear_anomaly_model_partition.hex)");
		return;
	}
#else
	nrf_edgeai_t *p_user_model = nrf_edgeai_user_model_90360();

	__ASSERT_NO_MSG(p_user_model != NULL);
#endif

	/* Validate that the loaded model matches our expected configuration */
	__ASSERT_NO_MSG(nrf_edgeai_input_window_size(p_user_model) == USER_WINDOW_SIZE);
	__ASSERT_NO_MSG(nrf_edgeai_uniq_inputs_num(p_user_model) == USER_UNIQ_INPUTS_NUM);

	/* Initialize Edge AI runtime for inference execution */
	nrf_edgeai_err_t res = nrf_edgeai_init(p_user_model);

	__ASSERT_NO_MSG(res == NRF_EDGEAI_ERR_SUCCESS);

	nrf_edgeai_rt_version_t v = nrf_edgeai_runtime_version();
	LOG_INF("nRF Edge AI runtime version: %d.%d.%d", v.field.major, v.field.minor,
		v.field.patch);

	flt32_t anomaly_score;
	const size_t DATA_LEN = USER_WINDOW_SIZE * USER_UNIQ_INPUTS_NUM;

	/* ---- TEST 1: Healthy Gear ---- */
	LOG_INF("--- Testing GOOD gear vibration data ---");
	LOG_INF("Expected: Low anomaly score (normal vibration pattern)");
	anomaly_score = model_predict(p_user_model, GOOD_GEAR_MECH_VIBRATION_DATA_2AXIS, DATA_LEN);

	LOG_INF("Anomaly score for GOOD gear data: %f", (double)anomaly_score);
	LOG_INF("Verdict: %s (score %s threshold)",
		anomaly_score < USER_ANOMALY_THRESHOLD ? "NORMAL" : "ANOMALY DETECTED",
		anomaly_score < USER_ANOMALY_THRESHOLD ? "<" : ">=");
	__ASSERT_NO_MSG(anomaly_score < USER_ANOMALY_THRESHOLD);

	/* ---- TEST 2: Faulty Gear ---- */
	LOG_INF("--- Testing ANOMALOUS gear vibration data ---");
	LOG_INF("Expected: High anomaly score (abnormal vibration pattern)");
	anomaly_score =
		model_predict(p_user_model, ANOMALOUS_GEAR_MECH_VIBRATION_DATA_2AXIS, DATA_LEN);

	LOG_INF("Anomaly score for ANOMALOUS gear data: %f", (double)anomaly_score);
	LOG_INF("Verdict: %s (score %s threshold)",
		anomaly_score < USER_ANOMALY_THRESHOLD ? "NORMAL" : "ANOMALY DETECTED",
		anomaly_score >= USER_ANOMALY_THRESHOLD ? ">=" : "<");
	__ASSERT_NO_MSG(anomaly_score >= USER_ANOMALY_THRESHOLD);

	LOG_INF("The model correctly distinguishes between healthy and faulty gears.");
}
```

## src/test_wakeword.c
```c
/*
 * Copyright (c) 2026 Nordic Semiconductor ASA
 *
 * SPDX-License-Identifier: LicenseRef-Nordic-5-Clause
 */

#include <nrf_edgeai/nrf_edgeai.h>

#include <nrf_edgeai_user_model.h>

#include <zephyr/kernel.h>
#include <zephyr/logging/log.h>

#if defined(CONFIG_MODEL_OTA_AXON)
#include <model_ota/model_ota_edgeai.h>

MODEL_OTA_EDGEAI_LOAD_DECL(36711);
#else
nrf_edgeai_t *nrf_edgeai_user_model_36711(void);
#endif

LOG_MODULE_REGISTER(multi_wakeword, LOG_LEVEL_INF);

#define WW_WINDOW_SIZE 160U

void run_wakeword_tests(void)
{
	static int16_t dummy_audio[WW_WINDOW_SIZE];

#if defined(CONFIG_MODEL_OTA_AXON)
	/* Model-only OTA: the compiled Axon model is loaded from its flash partition (XIP) at
	 * runtime and wired into the app-compiled nrf_edgeai_t wrapper.
	 */
	nrf_edgeai_t *model;

	if (nrf_edgeai_load_user_model_36711(&model) != MODEL_IMAGE_OK) {
		LOG_WRN("No valid wakeword model image in model_wakeword_storage - skipping "
			"(flash wakeword_model_partition.hex)");
		return;
	}
#else
	nrf_edgeai_t *model = nrf_edgeai_user_model_36711();

	__ASSERT_NO_MSG(model != NULL);
#endif

	__ASSERT_NO_MSG(nrf_edgeai_input_window_size(model) == WW_WINDOW_SIZE);
	__ASSERT_NO_MSG(nrf_edgeai_uniq_inputs_num(model) == 1U);

	nrf_edgeai_err_t err = nrf_edgeai_init(model);
	__ASSERT(err == NRF_EDGEAI_ERR_SUCCESS, "err %d", err);

	err = nrf_edgeai_feed_inputs(model, dummy_audio, WW_WINDOW_SIZE);
	__ASSERT(err == NRF_EDGEAI_ERR_SUCCESS, "err %d", err);

	err = nrf_edgeai_run_inference(model);
	__ASSERT(err == NRF_EDGEAI_ERR_INPROGRESS, "err %d", err);

	err = nrf_edgeai_feed_inputs(model, dummy_audio, WW_WINDOW_SIZE);
	__ASSERT(err == NRF_EDGEAI_ERR_SUCCESS, "err %d", err);

	err = nrf_edgeai_run_inference(model);
	__ASSERT(err == NRF_EDGEAI_ERR_INPROGRESS, "err %d", err);

	err = nrf_edgeai_feed_inputs(model, dummy_audio, WW_WINDOW_SIZE);
	__ASSERT(err == NRF_EDGEAI_ERR_SUCCESS, "err %d", err);

	err = nrf_edgeai_run_inference(model);
	__ASSERT(err == NRF_EDGEAI_ERR_SUCCESS, "err %d", err);

	const uint16_t predicted_class = model->decoded_output.classif.predicted_class;
	const float probability =
		model->decoded_output.classif.probabilities.p_f32[predicted_class];

	LOG_INF("Wakeword inference on dummy PCM: class %u, probability %f",
		predicted_class, (double)probability);
}
```
